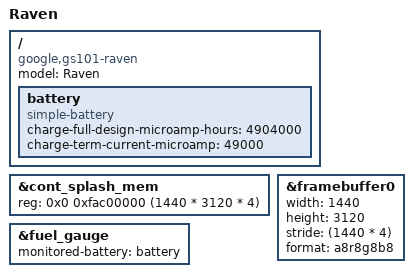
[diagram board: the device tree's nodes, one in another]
// SPDX-License-Identifier: GPL-2.0-only
/*
 * Raven Device Tree
 *
 * Copyright 2021-2023 Google LLC
 * Copyright 2023-2025 Linaro Ltd
 */

/dts-v1/;

#include "gs101-pixel-common.dtsi"

/ {
	model = "Raven";
	compatible = "google,gs101-raven", "google,gs101";

	battery: battery {
		compatible = "simple-battery";

		charge-full-design-microamp-hours = <4904000>;
		charge-term-current-microamp = <49000>;
	};
};

&cont_splash_mem {
	reg = <0x0 0xfac00000 (1440 * 3120 * 4)>;
	status = "okay";
};

&framebuffer0 {
	width = <1440>;
	height = <3120>;
	stride = <(1440 * 4)>;
	format = "a8r8g8b8";
	status = "okay";
};

&fuel_gauge {
	monitored-battery = <&battery>;
};
